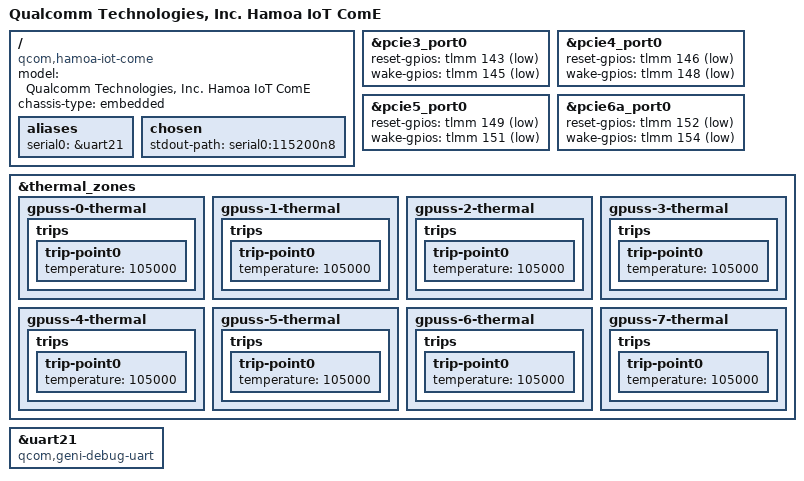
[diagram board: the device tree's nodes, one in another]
// SPDX-License-Identifier: BSD-3-Clause
/*
 * Copyright (c) Qualcomm Technologies, Inc. and/or its subsidiaries.
 */

/dts-v1/;

#include "hamoa-iot-come-som.dtsi"

/ {
	model = "Qualcomm Technologies, Inc. Hamoa IoT ComE";
	compatible = "qcom,hamoa-iot-come", "qcom,hamoa-iot-come-som",
		     "qcom,hamoa-iot-som", "qcom,x1e80100";
	chassis-type = "embedded";

	aliases {
		serial0 = &uart21;
	};

	chosen {
		stdout-path = "serial0:115200n8";
	};

};

&pcie3_port0 {
	reset-gpios = <&tlmm 143 GPIO_ACTIVE_LOW>;
	wake-gpios = <&tlmm 145 GPIO_ACTIVE_LOW>;
};

&pcie4_port0 {
	reset-gpios = <&tlmm 146 GPIO_ACTIVE_LOW>;
	wake-gpios = <&tlmm 148 GPIO_ACTIVE_LOW>;
};

&pcie5_port0 {
	reset-gpios = <&tlmm 149 GPIO_ACTIVE_LOW>;
	wake-gpios = <&tlmm 151 GPIO_ACTIVE_LOW>;
};

&pcie6a_port0 {
	reset-gpios = <&tlmm 152 GPIO_ACTIVE_LOW>;
	wake-gpios = <&tlmm 154 GPIO_ACTIVE_LOW>;
};

&thermal_zones {
	gpuss-0-thermal {
		trips {
			trip-point0 {
				temperature = <105000>;
			};
		};
	};

	gpuss-1-thermal {
		trips {
			trip-point0 {
				temperature = <105000>;
			};
		};
	};

	gpuss-2-thermal {
		trips {
			trip-point0 {
				temperature = <105000>;
			};
		};
	};

	gpuss-3-thermal {
		trips {
			trip-point0 {
				temperature = <105000>;
			};
		};
	};

	gpuss-4-thermal {
		trips {
			trip-point0 {
				temperature = <105000>;
			};
		};
	};

	gpuss-5-thermal {
		trips {
			trip-point0 {
				temperature = <105000>;
			};
		};
	};

	gpuss-6-thermal {
		trips {
			trip-point0 {
				temperature = <105000>;
			};
		};
	};

	gpuss-7-thermal {
		trips {
			trip-point0 {
				temperature = <105000>;
			};
		};
	};
};

&uart21 {
	compatible = "qcom,geni-debug-uart";

	status = "okay";
};
